# ATSAM4SDxC register map
Vendor: Atmel; Series: SAM4S; File version: 0
CPU: CM4 r0p1, selectable endian, MPU, no FPU, 4 interrupt priority bits
Registers are 32-bit, read-write, reset 0x0 unless marked. A register's access mark holds for its fields unless they carry their own. Offsets are from the block's base; [hi:lo] are bit positions; {n}, {i} and the like mark numbered series.

## CHIPID — Chip Identifier
Base 0x400E0740; register names take the prefix CHIPID_
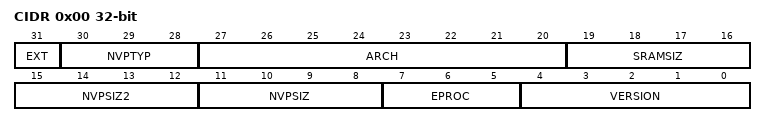
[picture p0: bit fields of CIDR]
0x00 CIDR ro reset not defined — Chip ID Register
  [31] EXT — Extension Flag
  [30:28] NVPTYP — Nonvolatile Program Memory Type
    0=ROM; 1=ROMLESS (ROMless or on-chip Flash); 2=FLASH (Embedded Flash Memory); 3=ROM_FLASH (ROM and Embedded Flash Memory- NVPSIZ is ROM size- NVPSIZ2 is Flash size); 4=SRAM (SRAM emulating ROM)
  [27:20] ARCH — Architecture Identifier
    136=SAM4SxA (48-pin version); 137=SAM4SxB (64-pin version); 138=SAM4SxC (100-pin version)
  [19:16] SRAMSIZ — Internal SRAM Size
    0=48K (48 Kbytes); 1=192K (192 Kbytes); 2=384K (384 Kbytes); 3=6K (6 Kbytes); 4=24K (24 Kbytes); 5=4K (4 Kbytes); 6=80K (80 Kbytes); 7=160K (160 Kbytes); 8=8K (8 Kbytes); 9=16K (16 Kbytes); 10=32K (32 Kbytes); 11=64K (64 Kbytes); 12=128K (128 Kbytes); 13=256K (256 Kbytes); 14=96K (96 Kbytes); 15=512K (512 Kbytes)
  [15:12] NVPSIZ2 — Second Nonvolatile Program Memory Size
    0=NONE; 1=8K (8 Kbytes); 2=16K (16 Kbytes); 3=32K (32 Kbytes); 5=64K (64 Kbytes); 7=128K (128 Kbytes); 9=256K (256 Kbytes); 10=512K (512 Kbytes); 12=1024K (1024 Kbytes); 14=2048K (2048 Kbytes)
  [11:8] NVPSIZ — Nonvolatile Program Memory Size
    0=NONE; 1=8K (8 Kbytes); 2=16K (16 Kbytes); 3=32K (32 Kbytes); 5=64K (64 Kbytes); 7=128K (128 Kbytes); 8=160K (160 Kbytes); 9=256K (256 Kbytes); 10=512K (512 Kbytes); 12=1024K (1024 Kbytes); 14=2048K (2048 Kbytes)
  [7:5] EPROC — Embedded Processor
    1=ARM946ES; 2=ARM7TDMI; 3=CM3 (Cortex-M3); 4=ARM920T; 5=ARM926EJS; 6=CA5 (Cortex-A5); 7=CM4 (Cortex-M4)
  [4:0] VERSION — Version of the Device
0x04 EXID ro reset not defined — Chip ID Extension Register
  [31:0] EXID — Chip ID Extension

## EFC0 — Embedded Flash Controller 0
Base 0x400E0A00; register names take the prefix EFC0_
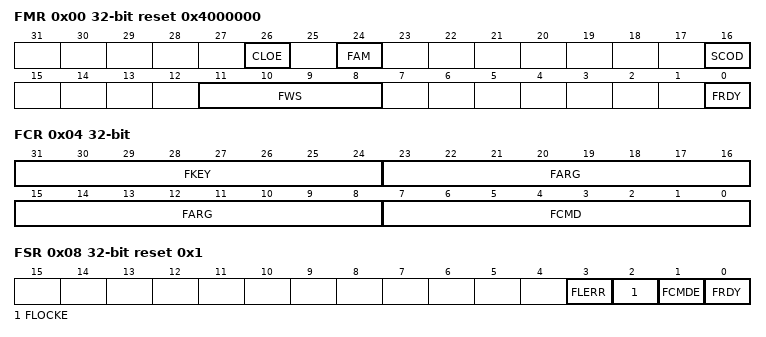
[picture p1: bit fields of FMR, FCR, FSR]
0x00 FMR reset 0x4000000 — EEFC Flash Mode Register
  [26] CLOE — Code Loop Optimization Enable
  [24] FAM — Flash Access Mode
  [16] SCOD — Sequential Code Optimization Disable
  [11:8] FWS — Flash Wait State
  [0] FRDY — Flash Ready Interrupt Enable
0x04 FCR wo reset not defined — EEFC Flash Command Register
  [31:24] FKEY — Flash Writing Protection Key
    90=PASSWD (The 0x5A value enables the command defined by the bits of the register. If the field is written with a different value, the write is not performed and no action is started.)
  [23:8] FARG — Flash Command Argument
  [7:0] FCMD — Flash Command
    0=GETD (Get Flash descriptor); 1=WP (Write page); 2=WPL (Write page and lock); 3=EWP (Erase page and write page); 4=EWPL (Erase page and write page then lock); 5=EA (Erase all); 7=EPA (Erase pages); 8=SLB (Set lock bit); 9=CLB (Clear lock bit); 10=GLB (Get lock bit); 11=SGPB (Set GPNVM bit); 12=CGPB (Clear GPNVM bit); 13=GGPB (Get GPNVM bit); 14=STUI (Start read unique identifier); 15=SPUI (Stop read unique identifier); 16=GCALB (Get CALIB bit); 17=ES (Erase sector); 18=WUS (Write user signature); 19=EUS (Erase user signature); 20=STUS (Start read user signature); 21=SPUS (Stop read user signature)
0x08 FSR ro reset 0x1 — EEFC Flash Status Register
  [3] FLERR — Flash Error Status (cleared when a programming operation starts)
  [2] FLOCKE — Flash Lock Error Status (cleared on read)
  [1] FCMDE — Flash Command Error Status (cleared on read or by writing EEFC_FCR)
  [0] FRDY — Flash Ready Status (cleared when Flash is busy)
0x0C FRR ro — EEFC Flash Result Register
  [31:0] FVALUE — Flash Result Value

## EFC1 — Embedded Flash Controller 1
Base 0x400E0C00; register names take the prefix EFC1_
Registers as EFC0.

## RSTC — Reset Controller
Base 0x400E1400; register names take the prefix RSTC_
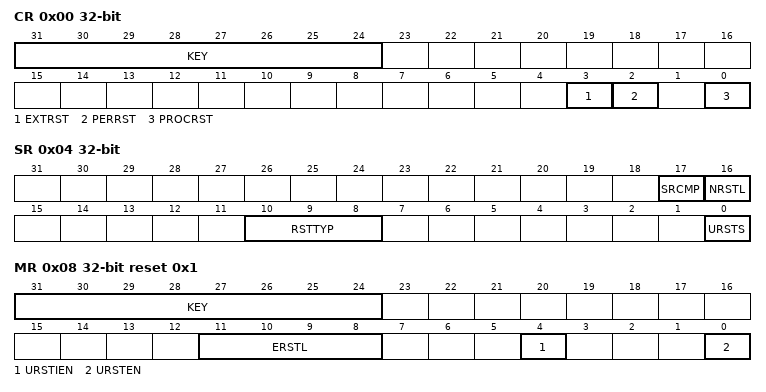
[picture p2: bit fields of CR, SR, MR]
0x00 CR wo reset not defined — Control Register
  [31:24] KEY — System Reset Key
    165=PASSWD (Writing any other value in this field aborts the write operation.)
  [3] EXTRST — External Reset
  [2] PERRST — Peripheral Reset
  [0] PROCRST — Processor Reset
0x04 SR ro reset not defined — Status Register
  [17] SRCMP — Software Reset Command in Progress
  [16] NRSTL — NRST Pin Level
  [10:8] RSTTYP — Reset Type
    0=GENERAL_RST (First power-up reset); 1=BACKUP_RST (Return from Backup Mode); 2=WDT_RST (Watchdog fault occurred); 3=SOFT_RST (Processor reset required by the software); 4=USER_RST (NRST pin detected low)
  [0] URSTS — User Reset Status
0x08 MR reset 0x1 — Mode Register
  [31:24] KEY — Write Access Password
    165=PASSWD (Writing any other value in this field aborts the write operation.Always reads as 0.)
  [11:8] ERSTL — External Reset Length
  [4] URSTIEN — User Reset Interrupt Enable
  [0] URSTEN — User Reset Enable

## RTT — Real-time Timer
Base 0x400E1430; register names take the prefix RTT_
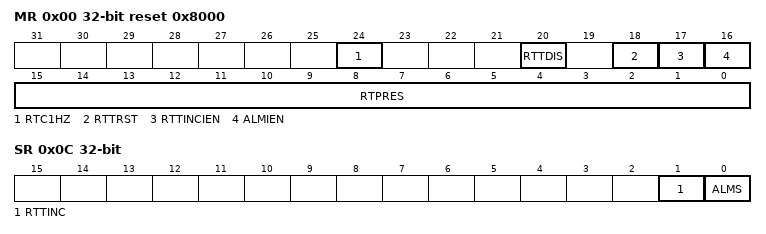
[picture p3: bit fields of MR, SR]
0x00 MR reset 0x8000 — Mode Register
  [24] RTC1HZ — Real-Time Clock 1Hz Clock Selection
  [20] RTTDIS — Real-time Timer Disable
  [18] RTTRST — Real-time Timer Restart
  [17] RTTINCIEN — Real-time Timer Increment Interrupt Enable
  [16] ALMIEN — Alarm Interrupt Enable
  [15:0] RTPRES — Real-time Timer Prescaler Value
0x04 AR reset 0xFFFFFFFF — Alarm Register
  [31:0] ALMV — Alarm Value
0x08 VR ro — Value Register
  [31:0] CRTV — Current Real-time Value
0x0C SR ro — Status Register
  [1] RTTINC — Prescaler Roll-over Status (cleared on read)
  [0] ALMS — Real-time Alarm Status (cleared on read)

## WDT — Watchdog Timer
Base 0x400E1450; register names take the prefix WDT_
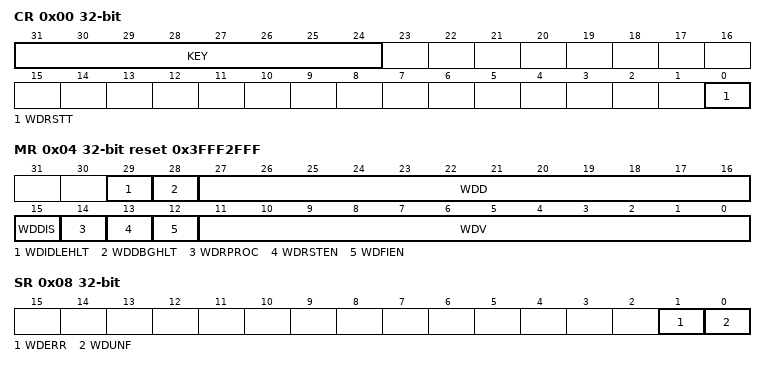
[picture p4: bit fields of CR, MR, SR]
0x00 CR wo reset not defined — Control Register
  [31:24] KEY — Password
    165=PASSWD (Writing any other value in this field aborts the write operation.)
  [0] WDRSTT — Watchdog Restart
0x04 MR reset 0x3FFF2FFF — Mode Register
  [29] WDIDLEHLT — Watchdog Idle Halt
  [28] WDDBGHLT — Watchdog Debug Halt
  [27:16] WDD — Watchdog Delta Value
  [15] WDDIS — Watchdog Disable
  [14] WDRPROC — Watchdog Reset Processor
  [13] WDRSTEN — Watchdog Reset Enable
  [12] WDFIEN — Watchdog Fault Interrupt Enable
  [11:0] WDV — Watchdog Counter Value
0x08 SR ro — Status Register
  [1] WDERR — Watchdog Error (cleared on read)
  [0] WDUNF — Watchdog Underflow (cleared on read)

## GPBR — General Purpose Backup Registers
Base 0x400E1490; register names take the prefix GPBR_
{0x0+4i} GPBR[{i}] (i=0..7) reset not defined — General Purpose Backup Register
  [31:0] GPBR_VALUE — Value of GPBR x

## Notices in the file
SAM Software Package License
Copyright (c) %copyright_year%, Atmel Corporation
All rights reserved.
Redistribution and use in source and binary forms, with or without
modification, are permitted provided that the following condition is met:
- Redistributions of source code must retain the above copyright notice,
this list of conditions and the disclaimer below.
Atmel's name may not be used to endorse or promote products derived from
this software without specific prior written permission.
DISCLAIMER:  THIS SOFTWARE IS PROVIDED BY ATMEL "AS IS" AND ANY EXPRESS OR
IMPLIED WARRANTIES, INCLUDING, BUT NOT LIMITED TO, THE IMPLIED WARRANTIES OF
MERCHANTABILITY, FITNESS FOR A PARTICULAR PURPOSE AND NON-INFRINGEMENT ARE
DISCLAIMED. IN NO EVENT SHALL ATMEL BE LIABLE FOR ANY DIRECT, INDIRECT,
INCIDENTAL, SPECIAL, EXEMPLARY, OR CONSEQUENTIAL DAMAGES (INCLUDING, BUT NOT
LIMITED TO, PROCUREMENT OF SUBSTITUTE GOODS OR SERVICES; LOSS OF USE, DATA,
OR PROFITS; OR BUSINESS INTERRUPTION) HOWEVER CAUSED AND ON ANY THEORY OF
LIABILITY, WHETHER IN CONTRACT, STRICT LIABILITY, OR TORT (INCLUDING
NEGLIGENCE OR OTHERWISE) ARISING IN ANY WAY OUT OF THE USE OF THIS SOFTWARE,
EVEN IF ADVISED OF THE POSSIBILITY OF SUCH DAMAGE.
